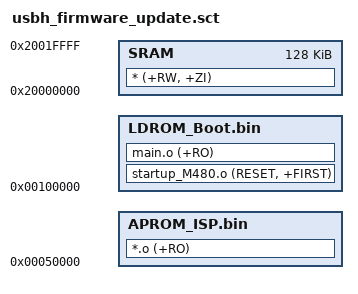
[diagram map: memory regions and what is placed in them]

LOAD_ROM_1  0x100000
{
	LDROM_Boot.bin  0x100000
	{
		startup_M480.o (RESET, +FIRST)
		main.o (+RO)
	}
	
	SRAM  0x20000000 0x20000
	{
		* (+RW, +ZI)
	}
}

LOAD_ROM_2  0x50000
{
	APROM_ISP.bin  0x50000
	{
		*.o (+RO)
	}
}



